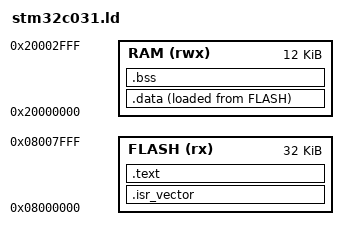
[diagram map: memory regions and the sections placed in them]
ENTRY(reset)

MEMORY
{
  FLASH (rx) : ORIGIN = 0x08000000, LENGTH = 32K
  RAM (rwx)  : ORIGIN = 0x20000000, LENGTH = 12K
}

SECTIONS
{
  .isr_vector : {
    KEEP(*(.isr_vector))
  } > FLASH

  .text : {
    *(.text*)
    *(.rodata*)
  } > FLASH

  _sidata = LOADADDR(.data);

  .data : {
    _sdata = .;
    *(.data*)
    _edata = .;
  } > RAM AT> FLASH

  .bss : {
    _sbss = .;
    __bss_start__ = .;
    *(.bss*)
    *(COMMON)
    _ebss = .;
    __bss_end__ = .;
  } > RAM

  end = .;
  _end = .;
}
